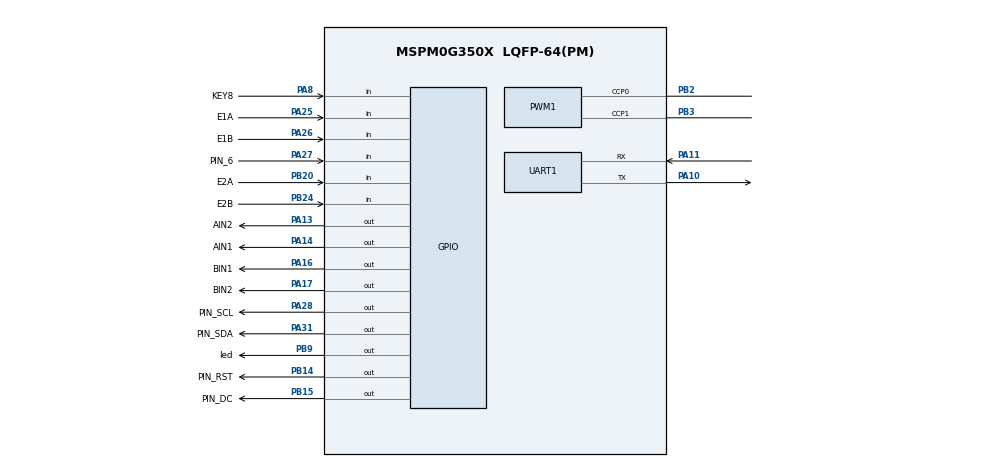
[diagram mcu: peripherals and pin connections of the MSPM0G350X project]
/**
 * @cliArgs --device "MSPM0G350X" --package "LQFP-64(PM)" --part "Default" --product "mspm0_sdk@2.01.00.03"
 * @versions {"tool":"1.20.0+3587"}
 */

/**
 * Import the modules used in this configuration.
 */
const GPIO    = scripting.addModule("/ti/driverlib/GPIO", {}, false);
const GPIO1   = GPIO.addInstance();
const GPIO2   = GPIO.addInstance();
const GPIO3   = GPIO.addInstance();
const GPIO4   = GPIO.addInstance();
const GPIO5   = GPIO.addInstance();
const GPIO6   = GPIO.addInstance();
const GPIO7   = GPIO.addInstance();
const GPIO8   = GPIO.addInstance();
const GPIO9   = GPIO.addInstance();
const GPIO10  = GPIO.addInstance();
const GPIO11  = GPIO.addInstance();
const GPIO12  = GPIO.addInstance();
const PWM     = scripting.addModule("/ti/driverlib/PWM", {}, false);
const PWM1    = PWM.addInstance();
const SYSCTL  = scripting.addModule("/ti/driverlib/SYSCTL");
const SYSTICK = scripting.addModule("/ti/driverlib/SYSTICK");
const TIMER   = scripting.addModule("/ti/driverlib/TIMER", {}, false);
const TIMER1  = TIMER.addInstance();
const UART    = scripting.addModule("/ti/driverlib/UART", {}, false);
const UART1   = UART.addInstance();

/**
 * Write custom configuration values to the imported modules.
 */
const divider7       = system.clockTree["PLL_PDIV"];
divider7.divideValue = 2;

const divider9       = system.clockTree["UDIV"];
divider9.divideValue = 2;

const gate7  = system.clockTree["MFCLKGATE"];
gate7.enable = true;

const multiplier2         = system.clockTree["PLL_QDIV"];
multiplier2.multiplyValue = 5;

const mux8       = system.clockTree["HSCLKMUX"];
mux8.inputSelect = "HSCLKMUX_SYSPLL2X";

GPIO1.$name                              = "KEY";
GPIO1.port                               = "PORTA";
GPIO1.associatedPins.create(2);
GPIO1.associatedPins[0].direction        = "INPUT";
GPIO1.associatedPins[0].internalResistor = "PULL_UP";
GPIO1.associatedPins[0].$name            = "KEY7";
GPIO1.associatedPins[0].assignedPin      = "7";
GPIO1.associatedPins[1].$name            = "KEY8";
GPIO1.associatedPins[1].direction        = "INPUT";
GPIO1.associatedPins[1].assignedPin      = "8";
GPIO1.associatedPins[1].internalResistor = "PULL_UP";
GPIO1.associatedPins[1].pin.$assign      = "PA8";

const Board = scripting.addModule("/ti/driverlib/Board", {}, false);

GPIO2.$name                         = "LED";
GPIO2.associatedPins[0].$name       = "led";
GPIO2.associatedPins[0].pin.$assign = "PB9";

GPIO3.port                          = "PORTA";
GPIO3.$name                         = "BIN";
GPIO3.associatedPins.create(2);
GPIO3.associatedPins[0].$name       = "BIN1";
GPIO3.associatedPins[0].pin.$assign = "PA16";
GPIO3.associatedPins[1].$name       = "BIN2";
GPIO3.associatedPins[1].pin.$assign = "PA17";

GPIO4.port                          = "PORTA";
GPIO4.$name                         = "AIN";
GPIO4.associatedPins.create(2);
GPIO4.associatedPins[0].$name       = "AIN1";
GPIO4.associatedPins[0].pin.$assign = "PA14";
GPIO4.associatedPins[1].$name       = "AIN2";
GPIO4.associatedPins[1].pin.$assign = "PA13";

GPIO5.$name                               = "ENCODERA";
GPIO5.associatedPins.create(2);
GPIO5.associatedPins[0].$name             = "E1A";
GPIO5.associatedPins[0].direction         = "INPUT";
GPIO5.associatedPins[0].polarity          = "RISE";
GPIO5.associatedPins[0].interruptPriority = "0";
GPIO5.associatedPins[0].interruptEn       = true;
GPIO5.associatedPins[0].pin.$assign       = "PA25";
GPIO5.associatedPins[1].$name             = "E1B";
GPIO5.associatedPins[1].direction         = "INPUT";
GPIO5.associatedPins[1].polarity          = "RISE";
GPIO5.associatedPins[1].interruptPriority = "0";
GPIO5.associatedPins[1].interruptEn       = true;
GPIO5.associatedPins[1].pin.$assign       = "PA26";

GPIO6.$name                               = "ENCODERB";
GPIO6.associatedPins.create(2);
GPIO6.associatedPins[0].$name             = "E2A";
GPIO6.associatedPins[0].direction         = "INPUT";
GPIO6.associatedPins[0].polarity          = "RISE";
GPIO6.associatedPins[0].interruptPriority = "0";
GPIO6.associatedPins[0].interruptEn       = true;
GPIO6.associatedPins[0].pin.$assign       = "PB20";
GPIO6.associatedPins[1].$name             = "E2B";
GPIO6.associatedPins[1].direction         = "INPUT";
GPIO6.associatedPins[1].polarity          = "RISE";
GPIO6.associatedPins[1].interruptPriority = "0";
GPIO6.associatedPins[1].interruptEn       = true;
GPIO6.associatedPins[1].pin.$assign       = "PB24";

GPIO7.$name                         = "OLED_SDA";
GPIO7.associatedPins[0].$name       = "PIN_SDA";
GPIO7.associatedPins[0].pin.$assign = "PA31";

GPIO8.$name                         = "OLED_SCL";
GPIO8.associatedPins[0].$name       = "PIN_SCL";
GPIO8.associatedPins[0].pin.$assign = "PA28";

GPIO9.$name                         = "OLED_DC";
GPIO9.associatedPins[0].$name       = "PIN_DC";
GPIO9.associatedPins[0].pin.$assign = "PB15";

GPIO10.$name                         = "OLED_RST";
GPIO10.associatedPins[0].$name       = "PIN_RST";
GPIO10.associatedPins[0].pin.$assign = "PB14";

GPIO11.port                               = "PORTA";
GPIO11.$name                              = "GW_Adress_A";
GPIO11.associatedPins.create(5);
GPIO11.associatedPins[0].$name            = "PIN_1";
GPIO11.associatedPins[0].assignedPin      = "12";
GPIO11.associatedPins[0].direction        = "INPUT";
GPIO11.associatedPins[0].internalResistor = "PULL_UP";
GPIO11.associatedPins[1].$name            = "PIN_6";
GPIO11.associatedPins[1].direction        = "INPUT";
GPIO11.associatedPins[1].internalResistor = "PULL_UP";
GPIO11.associatedPins[1].assignedPin      = "27";
GPIO11.associatedPins[1].pin.$assign      = "PA27";
GPIO11.associatedPins[2].$name            = "PIN_4";
GPIO11.associatedPins[2].direction        = "INPUT";
GPIO11.associatedPins[2].assignedPin      = "22";
GPIO11.associatedPins[2].internalResistor = "PULL_UP";
GPIO11.associatedPins[3].$name            = "PIN_5";
GPIO11.associatedPins[3].direction        = "INPUT";
GPIO11.associatedPins[3].assignedPin      = "24";
GPIO11.associatedPins[3].internalResistor = "PULL_UP";
GPIO11.associatedPins[4].$name            = "PIN_7";
GPIO11.associatedPins[4].direction        = "INPUT";
GPIO11.associatedPins[4].assignedPin      = "9";
GPIO11.associatedPins[4].internalResistor = "PULL_UP";

GPIO12.$name                              = "GW_Adress_B";
GPIO12.port                               = "PORTB";
GPIO12.associatedPins.create(2);
GPIO12.associatedPins[0].$name            = "PIN_2";
GPIO12.associatedPins[0].direction        = "INPUT";
GPIO12.associatedPins[0].assignedPin      = "16";
GPIO12.associatedPins[0].internalResistor = "PULL_UP";
GPIO12.associatedPins[1].$name            = "PIN_3";
GPIO12.associatedPins[1].direction        = "INPUT";
GPIO12.associatedPins[1].assignedPin      = "17";
GPIO12.associatedPins[1].internalResistor = "PULL_UP";

PWM1.$name                      = "PWM_0";
PWM1.timerStartTimer            = true;
PWM1.pwmMode                    = "EDGE_ALIGN_UP";
PWM1.clockPrescale              = 80;
PWM1.peripheral.$assign         = "TIMA1";
PWM1.peripheral.ccp0Pin.$assign = "PB2";
PWM1.peripheral.ccp1Pin.$assign = "PB3";
PWM1.PWM_CHANNEL_0.$name        = "ti_driverlib_pwm_PWMTimerCC0";
PWM1.PWM_CHANNEL_1.$name        = "ti_driverlib_pwm_PWMTimerCC1";
PWM1.ccp0PinConfig.$name        = "ti_driverlib_gpio_GPIOPinGeneric4";
PWM1.ccp1PinConfig.$name        = "ti_driverlib_gpio_GPIOPinGeneric5";

SYSCTL.forceDefaultClkConfig = true;
SYSCTL.clockTreeEn           = true;

SYSTICK.periodEnable  = true;
SYSTICK.systickEnable = true;
SYSTICK.period        = 16777216;

TIMER1.$name              = "TIMER_0";
TIMER1.timerMode          = "PERIODIC";
TIMER1.timerStartTimer    = true;
TIMER1.interrupts         = ["ZERO"];
TIMER1.timerClkPrescale   = 200;
TIMER1.timerPeriod        = "40ms";
TIMER1.peripheral.$assign = "TIMG0";

UART1.$name                    = "UART_0";
UART1.profile                  = "CONFIG_PROFILE_1";
UART1.peripheral.rxPin.$assign = "PA11";
UART1.peripheral.txPin.$assign = "PA10";
UART1.txPinConfig.$name        = "ti_driverlib_gpio_GPIOPinGeneric2";
UART1.rxPinConfig.$name        = "ti_driverlib_gpio_GPIOPinGeneric3";

/**
 * Pinmux solution for unlocked pins/peripherals. This ensures that minor changes to the automatic solver in a future
 * version of the tool will not impact the pinmux you originally saw.  These lines can be completely deleted in order to
 * re-solve from scratch.
 */
GPIO1.associatedPins[0].pin.$suggestSolution  = "PA7";
Board.peripheral.$suggestSolution             = "DEBUGSS";
Board.peripheral.swclkPin.$suggestSolution    = "PA20";
Board.peripheral.swdioPin.$suggestSolution    = "PA19";
GPIO11.associatedPins[0].pin.$suggestSolution = "PA12";
GPIO11.associatedPins[2].pin.$suggestSolution = "PA22";
GPIO11.associatedPins[3].pin.$suggestSolution = "PA24";
GPIO11.associatedPins[4].pin.$suggestSolution = "PA9";
GPIO12.associatedPins[0].pin.$suggestSolution = "PB16";
GPIO12.associatedPins[1].pin.$suggestSolution = "PB17";
UART1.peripheral.$suggestSolution             = "UART0";
